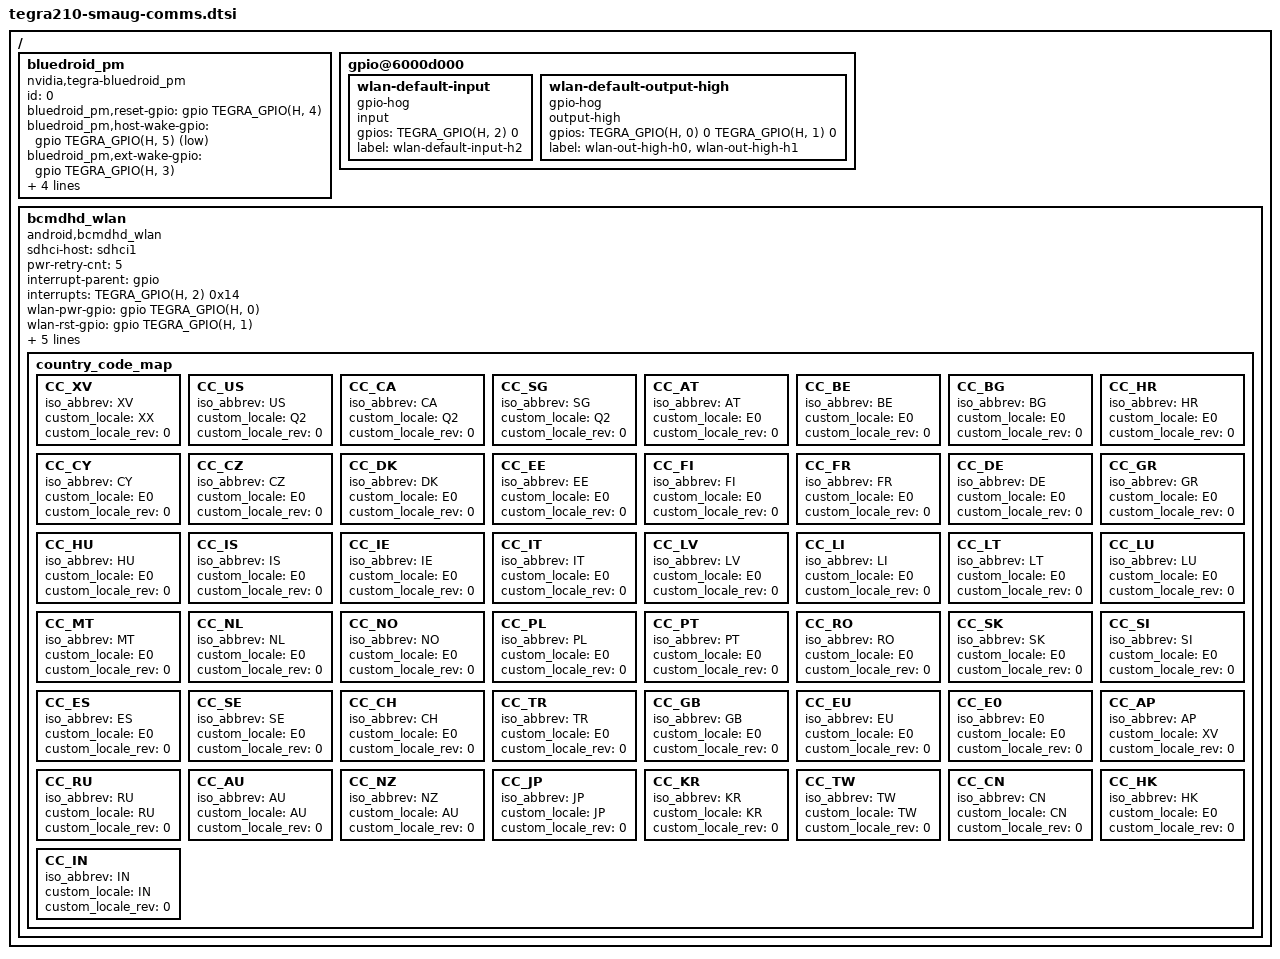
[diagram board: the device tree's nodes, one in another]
/*
 * Copyright (c) 2015-2016, NVIDIA CORPORATION.  All rights reserved.
 *
 * This program is free software; you can redistribute it and/or modify
 * it under the terms of the GNU General Public License as published by
 * the Free Software Foundation; version 2 of the License.
 *
 * This program is distributed in the hope that it will be useful, but WITHOUT
 * ANY WARRANTY; without even the implied warranty of MERCHANTABILITY or
 * FITNESS FOR A PARTICULAR PURPOSE.  See the GNU General Public License for
 * more details.
 *
 */
#include <dt-bindings/gpio/tegra-gpio.h>
#include <dt-bindings/soc/tegra-pmc.h>

/ {

	bluedroid_pm {
		status = "okay";
		compatible = "nvidia,tegra-bluedroid_pm";
		id = <0>;
		bluedroid_pm,reset-gpio = <&gpio TEGRA_GPIO(H, 4) 0>;
		bluedroid_pm,host-wake-gpio = <&gpio TEGRA_GPIO(H, 5) 1>;
		bluedroid_pm,ext-wake-gpio = <&gpio TEGRA_GPIO(H, 3) 0>;
		interrupt-parent = <&gpio>;
		interrupts = <TEGRA_GPIO(H, 5) 0x01>;
		nvidia,pmc-wakeup = <&tegra_pmc
			PMC_WAKE_TYPE_EVENT 52 PMC_TRIGGER_TYPE_HIGH>;
	};

	gpio@6000d000 {
		wlan-default-input {
			gpio-hog;
			input;
			gpios = <
				TEGRA_GPIO(H, 2) 0
				>;
			label = "wlan-default-input-h2";
		};

		wlan-default-output-high {
			gpio-hog;
			output-high;
			gpios = <
				TEGRA_GPIO(H, 0) 0
				 TEGRA_GPIO(H, 1) 0>;
			label = "wlan-out-high-h0", "wlan-out-high-h1";
		};
	};

	bcmdhd_wlan {
		compatible = "android,bcmdhd_wlan";
		sdhci-host = <&sdhci1>;
		pwr-retry-cnt = <5>;
		interrupt-parent = <&gpio>;
		interrupts = <TEGRA_GPIO(H, 2) 0x14>;
		wlan-pwr-gpio = <&gpio TEGRA_GPIO(H, 0) 0>;
		wlan-rst-gpio = <&gpio TEGRA_GPIO(H, 1) 0>;
		fw_path = "/vendor/firmware/fw_bcmdhd.bin";
		nv_path = "/vendor/firmware/nvram_smaug_4354.txt";
		clm_blob_path = "/vendor/firmware/bcmdhd_clm_foster.blob";
		status = "okay";
		builtin-roam-disabled;
		country_code_map {
			CC_XV {
				iso_abbrev = "XV";
				custom_locale = "XX";
				custom_locale_rev = <0>;
			};
			CC_US {
				iso_abbrev = "US";
				custom_locale = "Q2";
				custom_locale_rev = <0>;
			};
			CC_CA {
				iso_abbrev = "CA";
				custom_locale = "Q2";
				custom_locale_rev = <0>;
			};
			CC_SG {
				iso_abbrev = "SG";
				custom_locale = "Q2";
				custom_locale_rev = <0>;
			};

			CC_AT {
				iso_abbrev = "AT";
				custom_locale = "E0";
				custom_locale_rev = <0>;
			};
			CC_BE {
				iso_abbrev = "BE";
				custom_locale = "E0";
				custom_locale_rev = <0>;
			};
			CC_BG {
				iso_abbrev = "BG";
				custom_locale = "E0";
				custom_locale_rev = <0>;
			};
			CC_HR {
				iso_abbrev = "HR";
				custom_locale = "E0";
				custom_locale_rev = <0>;
			};
			CC_CY {
				iso_abbrev = "CY";
				custom_locale = "E0";
				custom_locale_rev = <0>;
			};
			CC_CZ {
				iso_abbrev = "CZ";
				custom_locale = "E0";
				custom_locale_rev = <0>;
			};
			CC_DK {
				iso_abbrev = "DK";
				custom_locale = "E0";
				custom_locale_rev = <0>;
			};
			CC_EE {
				iso_abbrev = "EE";
				custom_locale = "E0";
				custom_locale_rev = <0>;
			};
			CC_FI {
				iso_abbrev = "FI";
				custom_locale = "E0";
				custom_locale_rev = <0>;
			};
			CC_FR {
				iso_abbrev = "FR";
				custom_locale = "E0";
				custom_locale_rev = <0>;
			};
			CC_DE {
				iso_abbrev = "DE";
				custom_locale = "E0";
				custom_locale_rev = <0>;
			};
			CC_GR {
				iso_abbrev = "GR";
				custom_locale = "E0";
				custom_locale_rev = <0>;
			};
			CC_HU {
				iso_abbrev = "HU";
				custom_locale = "E0";
				custom_locale_rev = <0>;
			};
			CC_IS {
				iso_abbrev = "IS";
				custom_locale = "E0";
				custom_locale_rev = <0>;
			};
			CC_IE {
				iso_abbrev = "IE";
				custom_locale = "E0";
				custom_locale_rev = <0>;
			};
			CC_IT {
				iso_abbrev = "IT";
				custom_locale = "E0";
				custom_locale_rev = <0>;
			};
			CC_LV {
				iso_abbrev = "LV";
				custom_locale = "E0";
				custom_locale_rev = <0>;
			};
			CC_LI {
				iso_abbrev = "LI";
				custom_locale = "E0";
				custom_locale_rev = <0>;
			};
			CC_LT {
				iso_abbrev = "LT";
				custom_locale = "E0";
				custom_locale_rev = <0>;
			};
			CC_LU {
				iso_abbrev = "LU";
				custom_locale = "E0";
				custom_locale_rev = <0>;
			};
			CC_MT {
				iso_abbrev = "MT";
				custom_locale = "E0";
				custom_locale_rev = <0>;
			};
			CC_NL {
				iso_abbrev = "NL";
				custom_locale = "E0";
				custom_locale_rev = <0>;
			};
			CC_NO {
				iso_abbrev = "NO";
				custom_locale = "E0";
				custom_locale_rev = <0>;
			};
			CC_PL {
				iso_abbrev = "PL";
				custom_locale = "E0";
				custom_locale_rev = <0>;
			};
			CC_PT {
				iso_abbrev = "PT";
				custom_locale = "E0";
				custom_locale_rev = <0>;
			};
			CC_RO {
				iso_abbrev = "RO";
				custom_locale = "E0";
				custom_locale_rev = <0>;
			};
			CC_SK {
				iso_abbrev = "SK";
				custom_locale = "E0";
				custom_locale_rev = <0>;
			};
			CC_SI {
				iso_abbrev = "SI";
				custom_locale = "E0";
				custom_locale_rev = <0>;
			};
			CC_ES {
				iso_abbrev = "ES";
				custom_locale = "E0";
				custom_locale_rev = <0>;
			};
			CC_SE {
				iso_abbrev = "SE";
				custom_locale = "E0";
				custom_locale_rev = <0>;
			};
			CC_CH {
				iso_abbrev = "CH";
				custom_locale = "E0";
				custom_locale_rev = <0>;
			};
			CC_TR {
				iso_abbrev = "TR";
				custom_locale = "E0";
				custom_locale_rev = <0>;
			};
			CC_GB {
				iso_abbrev = "GB";
				custom_locale = "E0";
				custom_locale_rev = <0>;
			};
			CC_EU {
				iso_abbrev = "EU";
				custom_locale = "E0";
				custom_locale_rev = <0>;
			};
			CC_E0 {
				iso_abbrev = "E0";
				custom_locale = "E0";
				custom_locale_rev = <0>;
			};
			CC_AP {
				iso_abbrev = "AP";
				custom_locale = "XV";
				custom_locale_rev = <0>;
			};
			CC_RU {
				iso_abbrev = "RU";
				custom_locale = "RU";
				custom_locale_rev = <0>;
			};
			CC_AU {
				iso_abbrev = "AU";
				custom_locale = "AU";
				custom_locale_rev = <0>;
			};
			CC_NZ {
				iso_abbrev = "NZ";
				custom_locale = "AU";
				custom_locale_rev = <0>;
			};
			CC_JP {
				iso_abbrev = "JP";
				custom_locale = "JP";
				custom_locale_rev = <0>;
			};
			CC_KR {
				iso_abbrev = "KR";
				custom_locale = "KR";
				custom_locale_rev = <0>;
			};
			CC_TW {
				iso_abbrev = "TW";
				custom_locale = "TW";
				custom_locale_rev = <0>;
			};
			CC_CN {
				iso_abbrev = "CN";
				custom_locale = "CN";
				custom_locale_rev = <0>;
			};
			CC_HK {
				iso_abbrev = "HK";
				custom_locale = "E0";
				custom_locale_rev = <0>;
			};
			CC_IN {
				iso_abbrev = "IN";
				custom_locale = "IN";
				custom_locale_rev = <0>;
			};
		};
	};
};
